# ADSP-2183xW_HPC register map
Vendor: Analog Devices; Series: ADSP-2183xW_HPC; File version: 3.0.3.517
CPU: 
Registers are 32-bit, read-write, reset 0x0 unless marked. A register's access mark holds for its fields unless they carry their own. Offsets are from the block's base; [hi:lo] are bit positions; {n}, {i} and the like mark numbered series; 'fields as' and 'values as' point back to an identical list.

## PKTE0 — Security Packet Engine
Base 0x310CD000
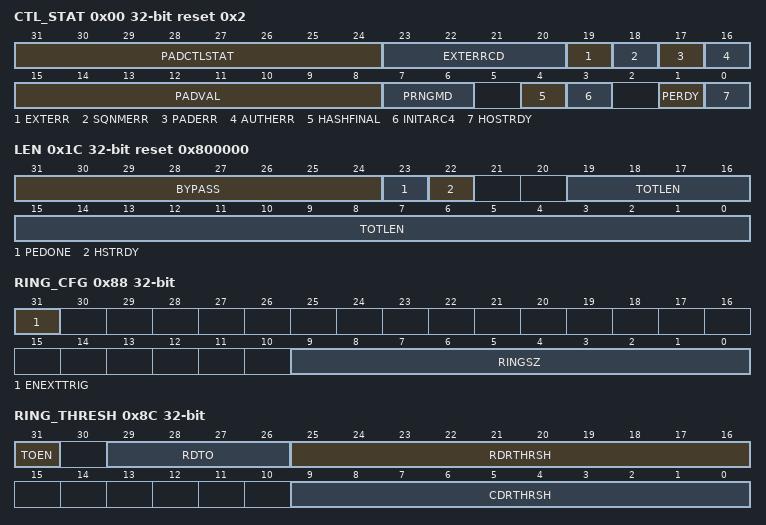
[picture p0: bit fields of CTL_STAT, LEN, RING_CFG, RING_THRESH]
0x00 CTL_STAT reset 0x2 — Packet Engine Control Register
  [31:24] PADCTLSTAT — Pad Control/Pad Status
  [23:20] EXTERRCD ro — Extended Error Code
  [19] EXTERR ro — Extended Error
  [18] SQNMERR ro — Sequence Number Error
  [17] PADERR ro — Pad Error
  [16] AUTHERR ro — Authentication Error
  [15:8] PADVAL range 0x00000000..0x000000FF — Pad Value
  [7:6] PRNGMD — PRNG Mode
  [4] HASHFINAL
  [3] INITARC4
  [1] PERDY range 0x00000000..0x00000001 — Packet Engine Ready
  [0] HOSTRDY range 0x00000000..0x00000001 — Host Ready
0x04 SRC_ADDR — Packet Engine Source Address
  [31:0] VALUE range 0x00000000..0xFFFFFFFF — Packet Source Address
0x08 DEST_ADDR — Packet Engine Destination Address
  [31:0] VALUE range 0x00000000..0xFFFFFFFF — Packet Destination Address
0x0C SA_ADDR — Packet Engine SA Address
  [31:0] VALUE range 0x00000000..0xFFFFFFFF — SA Record Address
0x10 STATE_ADDR — Packet Engine State Record Address
  [31:0] VALUE range 0x00000000..0xFFFFFFFF — State Record Address
0x14 ARC4STATE_ADDR — Packet Engine ARC4 State Record Address
  [31:0] VALUE range 0x00000000..0xFFFFFFFF — Arc4 State Record Address
0x18 USERID — Packet Engine User ID
  [31:0] VALUE range 0x00000000..0xFFFFFFFF — Command Descriptor User ID
0x1C LEN reset 0x800000 — Packet Engine Length Register
  [31:24] BYPASS range 0x00000000..0x000000FF
  [23] PEDONE range 0x00000000..0x00000001
  [22] HSTRDY ro — Host Ready
  [19:0] TOTLEN range 0x00000000..0x000FFFFF — Total length
0x80 CDRBASE_ADDR — Packet Engine Command Descriptor Ring Base Address
  [31:0] VALUE range 0x00000000..0xFFFFFFFF — Command Descriptor Ring Base Address
0x84 RDRBASE_ADDR — Packet Engine Result Descriptor Ring Base Address
  [31:0] VALUE range 0x00000000..0xFFFFFFFF — Result Descriptor Ring Base Address
0x88 RING_CFG — Packet Engine Ring Configuration
  [31] ENEXTTRIG range 0x00000000..0x00000001 — Enable External Trigger
  [9:0] RINGSZ range 0x00000000..0x000003FF — Ring Size
0x8C RING_THRESH — Packet Engine Ring Threshold Registers
  [31] TOEN range 0x00000000..0x00000001 — Timeout Enable
  [29:26] RDTO range 0x00000000..0x0000000F — Read Descriptor Timeout
  [25:16] RDRTHRSH range 0x00000000..0x000003FF — Result Descriptor Ring Threshold
  [9:0] CDRTHRSH range 0x00000000..0x000003FF — Command Descriptor Ring Threshold
0x90 CDSC_CNT — Packet Engine Command Descriptor Count Register
  [10:0] VALUE ro — Command Descriptor Count
0x90 CDSC_INCR (alternate view of CDSC_CNT) — Packet Engine Command Descriptor Count Increment Register
  [7:0] VALUE wo range 0x00000000..0x000000FF — Command Descriptor Count Increment
0x94 RDSC_CNT — Packet Engine Result Descriptor Count Registers
  [10:0] VALUE ro — Result Descriptor Count
0x94 RDSC_DECR (alternate view of RDSC_CNT) — Packet Engine Result Descriptor Count Decrement Registers
  [7:0] VALUE wo range 0x00000000..0x000000FF — Read Count Decrement
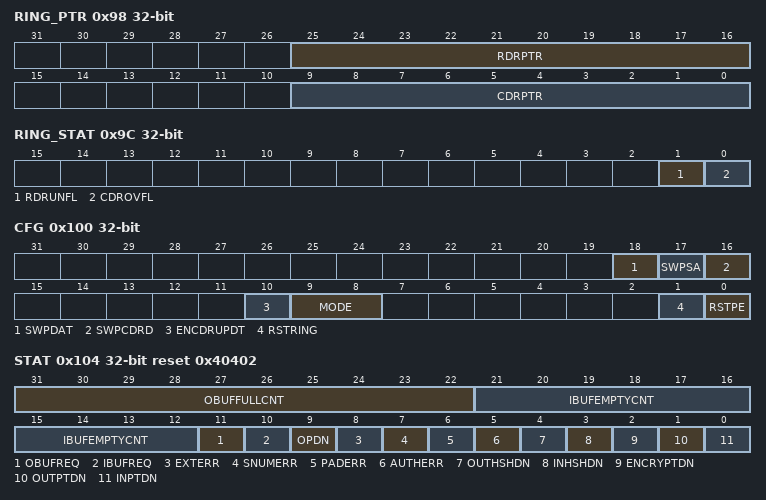
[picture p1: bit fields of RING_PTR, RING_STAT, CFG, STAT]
0x98 RING_PTR — Packet Engine Ring Pointer Status
  [25:16] RDRPTR ro — Result Descriptor Ring Write Pointer
  [9:0] CDRPTR ro — Command Descriptor Ring Read Pointer
0x9C RING_STAT — Packet Engine Ring Status
  [1] RDRUNFL ro — Result Descriptor Ring Underflow
  [0] CDROVFL ro — Command Descriptor Ring Overflow
0x100 CFG — Packet Engine Configuration Register
  [18] SWPDAT — Swap Data
  [17] SWPSA — Swap SA
  [16] SWPCDRD — Swap CD RD
  [10] ENCDRUPDT — Enable CDR Update
  [9:8] MODE — Packet Engine Mode
    0=HOST (Direct Host Mode.); 1=TCM0 (Target Command Mode with Result Descriptor Ring Disabled.); 2=TCM1 (Target Command Mode with Result Descriptor Ring Enabled.); 3=AUTO (Autonomous Ring Mode)
  [1] RSTRING — Reset Ring
  [0] RSTPE — Reset Packet Engine
0x104 STAT reset 0x40402 — Packet Engine Status Register
  [31:22] OBUFFULLCNT ro — Output Buffer Full Count
  [21:12] IBUFEMPTYCNT ro — Input Buffer Empty Count
  [11] OBUFREQ ro — Output Buffer Request Active
  [10] IBUFREQ ro — Input Buffer Request Active
  [9] OPDN ro — Operation Done
  [8] EXTERR ro — Extended Error
  [7] SNUMERR ro — Sequence Number Error
  [6] PADERR ro — Pad Error
  [5] AUTHERR ro — Authentication Error
  [4] OUTHSHDN ro — Outer Hash Done
  [3] INHSHDN ro — Inner Hash Done
  [2] ENCRYPTDN ro — Encrypt Done
  [1] OUTPTDN ro — PE Output Done
  [0] INPTDN ro — Packet Engine Input Done
0x108 PE_ALT_KEY_STATUS — PE Alternative Key stat register
  [7:0] ALT_KEY_X_W range 0x00000000..0x000000FF — Written status for each ALT_KEY_X
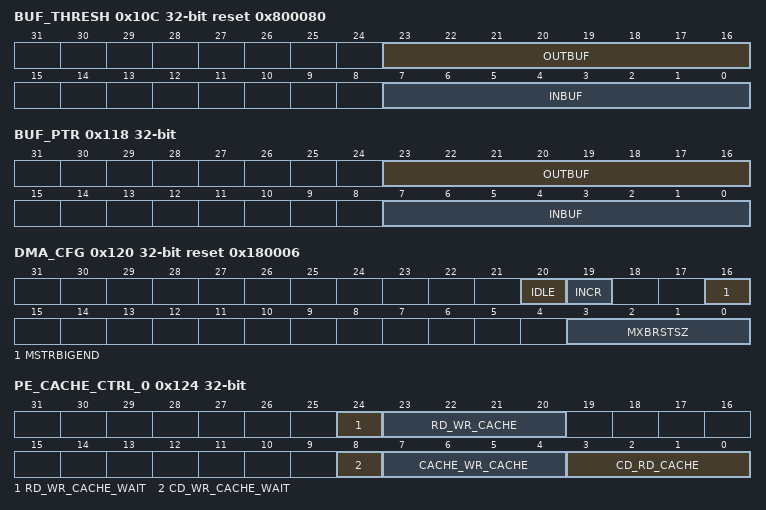
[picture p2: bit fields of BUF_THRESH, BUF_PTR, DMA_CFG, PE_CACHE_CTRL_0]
0x10C BUF_THRESH reset 0x800080 — Packet Engine Buffer Threshold Register
  [23:16] OUTBUF range 0x00000000..0x000000FF — Output Buffer Threshold
  [7:0] INBUF range 0x00000000..0x000000FF — Input Buffer Threshold
0x110 INBUF_CNT — Packet Engine Input Buffer Count Register
  [8:0] VALUE ro — Input Buffer Count
0x110 INBUF_INCR (alternate view of INBUF_CNT) — Packet Engine Input Buffer Count Increment Register
  [8:0] VALUE wo range 0x00000000..0x000001FF — Input Buffer Increment
0x114 OUTBUF_CNT — Packet Engine Output Buffer Count Register
  [8:0] VALUE ro — Output Buffer Count
0x114 OUTBUF_DECR (alternate view of OUTBUF_CNT) — Packet Engine Output Buffer Count Decrement Register
  [8:0] VALUE range 0x00000000..0x000001FF — Output Buffer Count Decrement
0x118 BUF_PTR — Packet Engine Buffer Pointer Register
  [23:16] OUTBUF ro — Output Buffer Pointer
  [7:0] INBUF ro — Input Buffer Pointer
0x120 DMA_CFG reset 0x180006 — Packet Engine DMA Configuration Register
  [20] IDLE ro — Idle Enable
  [19] INCR ro — Increment Enable
  [16] MSTRBIGEND ro — Requester Big Endian
  [3:0] MXBRSTSZ range 0x00000000..0x0000000F — Max Burst Size
0x124 PE_CACHE_CTRL_0 — Packet Engine Cache Control 0
  [24] RD_WR_CACHE_WAIT range 0x00000000..0x00000001 — AXI response wait enable control for Result Descriptor DMA writes
  [23:20] RD_WR_CACHE range 0x00000000..0x0000000F — Result Descriptor write cache type control
  [8] CD_WR_CACHE_WAIT range 0x00000000..0x00000001 — AXI response wait enable control for Command Descriptor DMA writes
  [7:4] CACHE_WR_CACHE range 0x00000000..0x0000000F — Cmd Descriptor write cache type control
  [3:0] CD_RD_CACHE range 0x00000000..0x0000000F — Cmd descriptor read cache type control
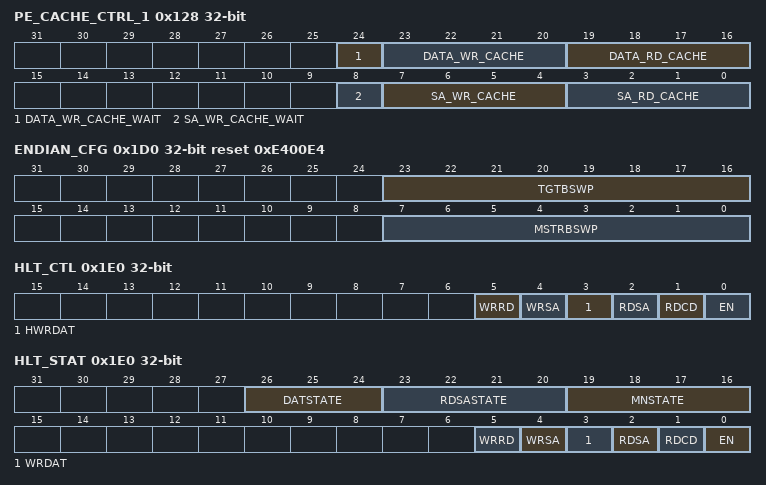
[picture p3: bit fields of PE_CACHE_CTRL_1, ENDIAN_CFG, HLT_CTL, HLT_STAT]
0x128 PE_CACHE_CTRL_1 — Packet Engine Cache Control 1
  [24] DATA_WR_CACHE_WAIT range 0x00000000..0x00000001 — AXI response wait enable control for data DMA writes
  [23:20] DATA_WR_CACHE range 0x00000000..0x0000000F — Data write cache type control
  [19:16] DATA_RD_CACHE range 0x00000000..0x0000000F — Data read cache type control
  [8] SA_WR_CACHE_WAIT range 0x00000000..0x00000001 — AXI response wait enable control for SA and (ARC4) Stare record DMA writes
  [7:4] SA_WR_CACHE range 0x00000000..0x0000000F — SA and (ARC4) Stare record write cache type control
  [3:0] SA_RD_CACHE range 0x00000000..0x0000000F — SA and (ARC4) Stare record read cache type control
0x1D0 ENDIAN_CFG reset 0xE400E4 — Packet Engine Endian Configuration Register
  [23:16] TGTBSWP range 0x00000000..0x000000FF — Target Byte Swap
  [7:0] MSTRBSWP range 0x00000000..0x000000FF — Requester Byte Swap
0x1E0 HLT_CTL — Packet Engine Halt Control Register
  [5] WRRD wo — Halt On Write Result Descriptor
  [4] WRSA wo — Halt On Write SA
  [3] HWRDAT wo — Halt On Write Data
  [2] RDSA wo — Halt On Read SA
  [1] RDCD wo — Halt On Read Command Descriptor
  [0] EN wo — Enable Halt Mode
0x1E0 HLT_STAT (alternate view of HLT_CTL) — Packet Engine Halt Status Register
  [26:24] DATSTATE ro — Data State
  [23:20] RDSASTATE ro — Read SA State
  [19:16] MNSTATE ro — Main State
  [5] WRRD ro — Halt On Write Result Descriptor
  [4] WRSA ro — Halt On Write SA
  [3] WRDAT ro — Halt On Write Data
  [2] RDSA ro — Halt On Read SA
  [1] RDCD ro — Halt On Read Command Descriptor
  [0] EN ro — Halt Mode Enabled Status
0x1E4 CONT — PKTE Continue Register
  [31:0] VALUE wo range 0x00000000..0xFFFFFFFF — Continue Operating
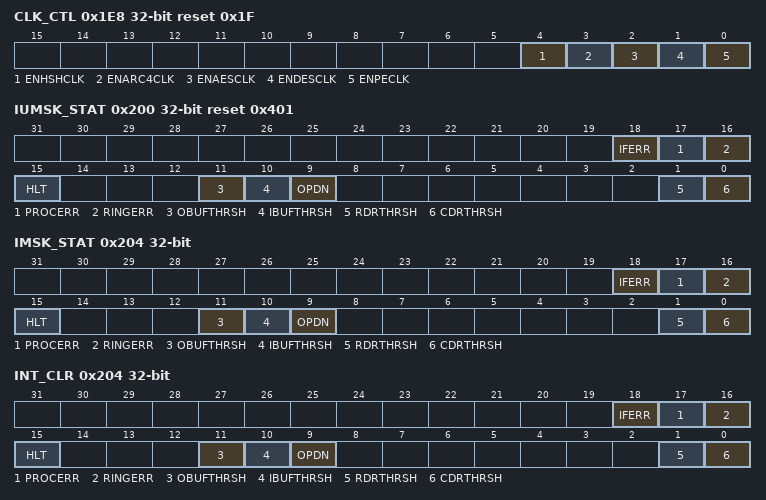
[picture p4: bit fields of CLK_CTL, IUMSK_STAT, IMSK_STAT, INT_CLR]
0x1E8 CLK_CTL reset 0x1F — PE Clock Control Register
  [4] ENHSHCLK — Enable Hash Clock
  [3] ENARC4CLK — Enable ARC4 Clock
  [2] ENAESCLK — Enable AES Clock
  [1] ENDESCLK — Enable DES Clock
  [0] ENPECLK — Enable Packet Engine Clock
0x200 IUMSK_STAT reset 0x401 — Interrupt Unmasked Status Register
  [18] IFERR ro — Interface Error
  [17] PROCERR ro — PKTE Processing Error
  [16] RINGERR ro — PKTE Ring Error
  [15] HLT ro — Halt
  [11] OBUFTHRSH ro — Output Buffer Threshold
  [10] IBUFTHRSH ro — Input Buffer Threshold
  [9] OPDN ro — Operation Done
  [1] RDRTHRSH ro — RDR Threshold
  [0] CDRTHRSH ro — CDR Threshold
0x204 IMSK_STAT — Interrupt Masked Status Register
  [18] IFERR ro — Interface Error
  [17] PROCERR ro — PKTE Processing Error
  [16] RINGERR ro — PE Ring Error
  [15] HLT ro — Halt
  [11] OBUFTHRSH ro — Output Buffer Threshold
  [10] IBUFTHRSH ro — Input Buffer Threshold
  [9] OPDN ro — Operation Done
  [1] RDRTHRSH ro — RDR Threshold
  [0] CDRTHRSH ro — CDR Threshold
0x204 INT_CLR (alternate view of IMSK_STAT) — Interrupt Clear Register
  [18] IFERR wo range 0x00000000..0x00000001 — Interface Error
  [17] PROCERR wo range 0x00000000..0x00000001 — PKTE Processing Error
  [16] RINGERR wo range 0x00000000..0x00000001 — PKTE Ring Error
  [15] HLT wo range 0x00000000..0x00000001 — Halt
  [11] OBUFTHRSH wo range 0x00000000..0x00000001 — Output Buffer Threshold
  [10] IBUFTHRSH wo range 0x00000000..0x00000001 — Input Buffer Threshold
  [9] OPDN wo range 0x00000000..0x00000001 — Operation Done
  [1] RDRTHRSH wo range 0x00000000..0x00000001 — RDR Threshold
  [0] CDRTHRSH wo range 0x00000000..0x00000001 — CDR Threshold
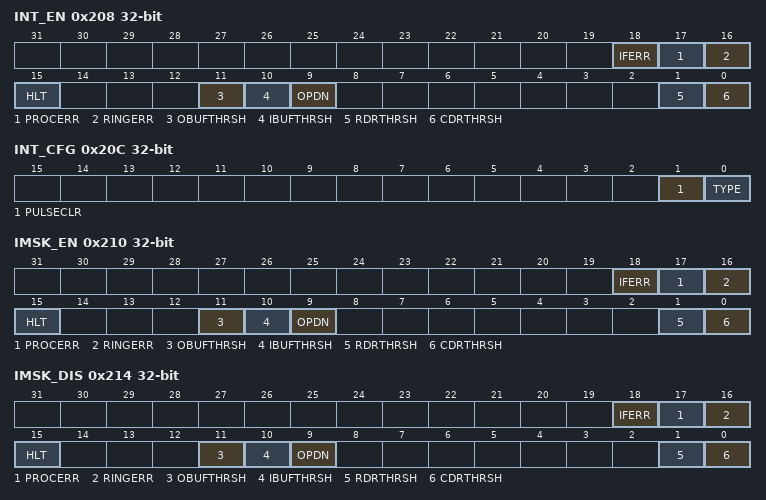
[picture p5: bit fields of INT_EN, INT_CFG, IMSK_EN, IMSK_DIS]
0x208 INT_EN — Interrupt Enable Register
  [18] IFERR range 0x00000000..0x00000001 — Interface Error
  [17] PROCERR range 0x00000000..0x00000001 — PKTE Processing Error
  [16] RINGERR range 0x00000000..0x00000001 — PKTE Ring Error
  [15] HLT range 0x00000000..0x00000001 — Halt
  [11] OBUFTHRSH range 0x00000000..0x00000001 — Output Buffer Threshold
  [10] IBUFTHRSH range 0x00000000..0x00000001 — Input Buffer Threshold
  [9] OPDN range 0x00000000..0x00000001 — Operation Done
  [1] RDRTHRSH range 0x00000000..0x00000001 — RDR Threshold
  [0] CDRTHRSH range 0x00000000..0x00000001 — CDR Threshold
0x20C INT_CFG — Interrupt Configuration Register
  [1] PULSECLR — Clear After Pulse Interrupt
  [0] TYPE — Interrupt Type
0x210 IMSK_EN — Interrupt Mask Enable Register
  fields as INT_CLR
0x214 IMSK_DIS — Interrupt Mask Disable Register
  fields as INT_CLR
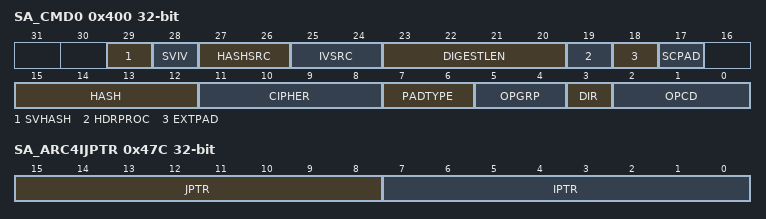
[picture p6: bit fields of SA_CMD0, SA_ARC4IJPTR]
0x400 SA_CMD0 — SA Command 0
  [29] SVHASH — Save Hash
  [28] SVIV — Save IV
  [27:26] HASHSRC — Hash Source
  [25:24] IVSRC — IV Source
  [23:20] DIGESTLEN — Digest Length
  [19] HDRPROC — Header Processing
  [18] EXTPAD range 0x00000000..0x00000001 — Extended Pad
  [17] SCPAD range 0x00000000..0x00000001 — Stream Cipher Padding
  [15:12] HASH — Hash Algorithm Select
  [11:8] CIPHER — Cipher Algorithm Select
  [7:6] PADTYPE
  [5:4] OPGRP — Operation Group
  [3] DIR — Direction
  [2:0] OPCD range 0x00000000..0x00000007 — Operation Code
0x404 SA_CMD1 — SA Command 1
  [29] ENSQNCHK — Sequence Number Check Enable
  [28] AESDECKEY
  [26:24] AESKEYLEN — AES Key Length
  [28:24] ARC4KEYLEN range 0x00000000..0x0000001F — ARC4 Key Length
  [23:16] HSHCOFFST range 0x00000000..0x000000FF — Hash Crypt Offset
  [13] BYTEOFFST — Byte Offset
  [12] HMAC — Keyed-Hash SSL Message Authentication Code
  [11] SSLMAC
  [9:8] CIPHERMD — Cipher Mode
  [3] CPYPAD — Copy Pad
  [2] CPYPAYLD — Copy Payload
  [1] CPYHDR — Copy Header
  [0] CPYDGST — Copy Digest
{0x408+4i} SA_KEY[{i}] (i=0..7) — SA Key Registers
  [31:0] VALUE wo range 0x00000000..0xFFFFFFFF — Cipher Key
{0x428+4i} SA_IDIGEST[{i}] (i=0..7) — SA Inner Hash Digest Registers
  [31:0] VALUE range 0x00000000..0xFFFFFFFF — Inner Hash Digest
{0x448+4i} SA_ODIGEST[{i}] (i=0..7) — SA Outer Hash Digest Registers
  [31:0] VALUE wo range 0x00000000..0xFFFFFFFF — Outer Hash Digest
0x468 SA_SPI
  [31:0] VALUE range 0x00000000..0xFFFFFFFF — SA SPI
0x46C SA_SEQNUM[0] — SA Sequence Number Register
  [31:0] VALUE range 0x00000000..0xFFFFFFFF — SA Sequence Number
0x470 SA_SEQNUM[1] — SA Sequence Number Register
  [31:0] VALUE range 0x00000000..0xFFFFFFFF — SA Sequence Number
0x474 SA_SEQNUM_MSK[0] — SA Sequence Number Mask Registers
  [31:0] VALUE range 0x00000000..0xFFFFFFFF — SA Sequence Number
0x478 SA_SEQNUM_MSK[1] — SA Sequence Number Mask Registers
  [31:0] VALUE range 0x00000000..0xFFFFFFFF — SA Sequence Number
0x47C SA_ARC4IJPTR — ARC4 i and j Pointer Register
  [15:8] JPTR range 0x00000000..0x000000FF — J Pointer
  [7:0] IPTR range 0x00000000..0x000000FF — I Pointer
0x47C SA_NONCE (alternate view of SA_ARC4IJPTR) — SA Initialization Vector Register
  [31:0] VALUE range 0x00000000..0xFFFFFFFF — SA Nonce
0x47C SA_RDY (alternate view of SA_ARC4IJPTR) — SA Ready Indicator
  [31:0] VALUE range 0x00000000..0xFFFFFFFF — SA Ready
{0x500+4i} STATE_IV[{i}] (i=0..3) — State Initialization Vector Registers
  [31:0] VALUE range 0x00000000..0xFFFFFFFF — State Initialization Vector
0x510 STATE_BYTE_CNT[0] — State Hash Byte Count Registers
  [31:0] VALUE range 0x00000000..0xFFFFFFFF — STATE Byte Count
0x514 STATE_BYTE_CNT[1] — State Hash Byte Count Registers
  [31:0] VALUE range 0x00000000..0xFFFFFFFF — STATE Byte Count
{0x518+4i} STATE_IDIGEST[{i}] (i=0..7) — State Inner Digest Registers
  [31:0] VALUE range 0x00000000..0xFFFFFFFF — Saved Inner Hash Digest
0x700 ARC4STATE_BUF — Starting Entry of 256-byte ARC4 State Buffer
  [31:0] VALUE range 0x00000000..0xFFFFFFFF — Buffer value
0x800 DATAIO_BUF — Starting Entry of 256-byte Data Input/Output Buffer
  [31:0] VALUE range 0x00000000..0xFFFFFFFF — Buffer Value
